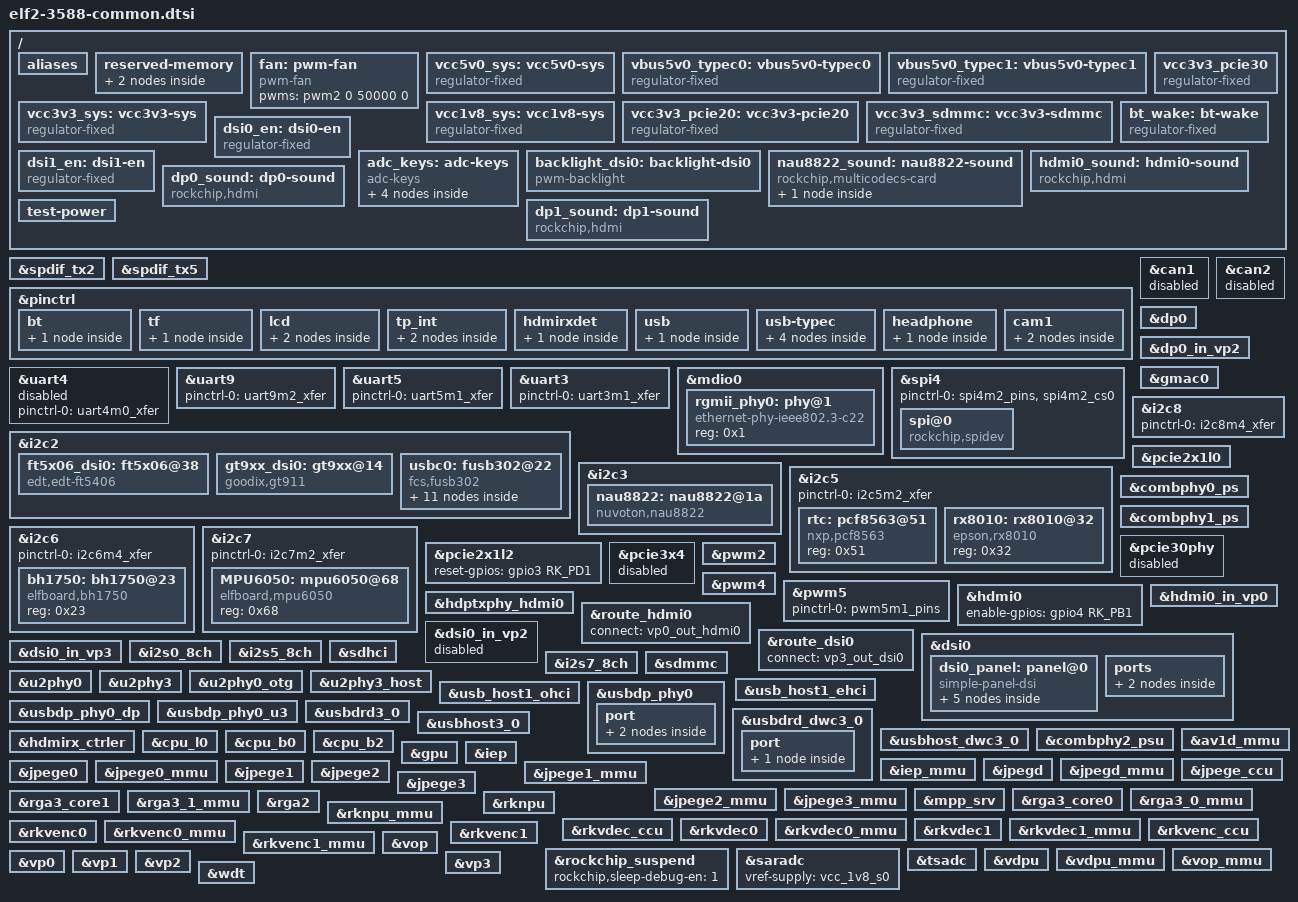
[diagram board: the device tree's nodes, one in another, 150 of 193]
//Readme
//本dtsi由ELF2的ubuntu系统全编译后导出
//修改点：IIC6、IIC7、IIC8、UART3、UART5引脚复用
//Readme

#include "dt-bindings/usb/pd.h"
#include <dt-bindings/gpio/gpio.h>
#include <dt-bindings/pwm/pwm.h>
#include <dt-bindings/pinctrl/rockchip.h>
#include <dt-bindings/input/rk-input.h>
#include <dt-bindings/display/drm_mipi_dsi.h>
#include <dt-bindings/display/rockchip_vop.h>
#include <dt-bindings/sensor-dev.h>

#include "rk3588.dtsi"
#include "elf2-3588.dtsi"
#include "rk3588-rk806-single.dtsi"
#include "elf2-3588-Camera.dtsi"

/ {
	aliases {
	        mmc0 = &sdhci;
	        mmc1 = &sdmmc;
	};

	reserved-memory {
		#address-cells = <2>;
		#size-cells = <2>;
		ranges;
		dma_trans: dma-trans@3c000000 {
			reg = <0x0 0x3c000000 0x0 0x04000000>;
		};

		/* Reserve 256MB memory for hdmirx-controller@fdee0000 */
		cma {
			compatible = "shared-dma-pool";
			reusable;
			reg = <0x0 (256 * 0x100000) 0x0 (256 * 0x100000)>;
			linux,cma-default;
		};
	};

	fan: pwm-fan {
		compatible = "pwm-fan";
		#cooling-cells = <2>;
		pwms = <&pwm2 0 50000 0>;
	};

	vcc5v0_sys: vcc5v0-sys {
		compatible = "regulator-fixed";
		regulator-name = "vcc5v0_sys";
		regulator-always-on;
		regulator-boot-on;
		regulator-min-microvolt = <5000000>;
		regulator-max-microvolt = <5000000>;
		vin-supply = <&vcc12v_dcin>;
	};

    vbus5v0_typec0: vbus5v0-typec0 {
        compatible = "regulator-fixed";
        regulator-name = "vbus5v0_typec0";
        regulator-min-microvolt = <5000000>;
        regulator-max-microvolt = <5000000>;
        enable-active-high;
        gpio = <&gpio0 RK_PD0 GPIO_ACTIVE_HIGH>;
        vin-supply = <&vcc5v0_sys>;
        pinctrl-names = "default";
        pinctrl-0 = <&typec5v_pwren0>;
    };

    vbus5v0_typec1: vbus5v0-typec1 {
        compatible = "regulator-fixed";
        regulator-name = "vbus5v0_typec1";
        regulator-min-microvolt = <5000000>;
        regulator-max-microvolt = <5000000>;
        enable-active-high;
        gpio = <&gpio0 RK_PD3 GPIO_ACTIVE_HIGH>;
        vin-supply = <&vcc5v0_sys>;
        pinctrl-names = "default";
        pinctrl-0 = <&typec5v_pwren1>;
    };

	vcc3v3_sys: vcc3v3-sys {
		compatible = "regulator-fixed";
		regulator-name = "vcc3v3_sys";
		regulator-always-on;
		regulator-boot-on;
		regulator-min-microvolt = <3300000>;
		regulator-max-microvolt = <3300000>;
		vin-supply = <&vcc5v0_sys>;
	};

	vcc1v8_sys: vcc1v8-sys {
		compatible = "regulator-fixed";
		regulator-name = "vcc1v8_sys";
		regulator-always-on;
		regulator-boot-on;
		regulator-min-microvolt = <1800000>;
		regulator-max-microvolt = <1800000>;
		vin-supply = <&vcc3v3_sys>;
	};

	vcc3v3_pcie30: vcc3v3_pcie30 {
		compatible = "regulator-fixed";
		regulator-name = "vcc3v3_pcie30";
		regulator-boot-on;
		regulator-always-on;
		regulator-min-microvolt = <3300000>;
		regulator-max-microvolt = <3300000>;
		vin-supply = <&vcc5v0_sys>;
	};

	vcc3v3_pcie20: vcc3v3-pcie20 {
		compatible = "regulator-fixed";
		regulator-name = "vcc3v3-pcie20";
		regulator-boot-on;
		regulator-always-on;
		regulator-min-microvolt = <3300000>;
		regulator-max-microvolt = <3300000>;
		vin-supply = <&vcc5v0_sys>;
	};

	vcc3v3_sdmmc: vcc3v3-sdmmc {
		compatible = "regulator-fixed";
		regulator-name = "vcc3v3_sdmmc";
		regulator-min-microvolt = <3300000>;
		regulator-max-microvolt = <3300000>;
		enable-active-high;
		regulator-boot-on;
		regulator-always-on;
		gpios = <&gpio2 RK_PC4 GPIO_ACTIVE_HIGH>;
		startup-delay-us = <5000>;
		vin-supply = <&vcc5v0_sys>;
	};

	bt_wake: bt-wake {
		compatible = "regulator-fixed";
		regulator-name = "bt_wake";
		regulator-min-microvolt = <1800000>;
		regulator-max-microvolt = <1800000>;
		enable-active-high;
		regulator-boot-on;
		regulator-always-on;
		gpios = <&gpio1 RK_PA6 GPIO_ACTIVE_HIGH>;
		vin-supply = <&vcc5v0_sys>;
	};

	dsi0_en: dsi0-en {
		compatible = "regulator-fixed";
		pinctrl-names = "default";
		pinctrl-0 = <&mipi0_enable_gpio>;
		regulator-name = "dsi0_en";
		regulator-min-microvolt = <1800000>;
		regulator-max-microvolt = <1800000>;
		enable-active-high;
		regulator-boot-on;
		regulator-always-on;
		gpios = <&gpio3 RK_PB2 GPIO_ACTIVE_HIGH>;
		vin-supply = <&vcc5v0_sys>;
	};
	dsi1_en: dsi1-en {
		compatible = "regulator-fixed";
		pinctrl-names = "default";
		pinctrl-0 = <&mipi1_enable_gpio>;
		regulator-name = "dsi1_en";
		regulator-min-microvolt = <1800000>;
		regulator-max-microvolt = <1800000>;
		enable-active-high;
		regulator-boot-on;
		regulator-always-on;
		gpios = <&gpio3 RK_PC6 GPIO_ACTIVE_HIGH>;
		vin-supply = <&vcc5v0_sys>;
	};

	adc_keys: adc-keys {
		compatible = "adc-keys";
		io-channels = <&saradc 1>;
		io-channel-names = "buttons";
		keyup-threshold-microvolt = <1800000>;
		poll-interval = <100>;

		vol-up-key {
			label = "volume up";
			linux,code = <KEY_VOLUMEUP>;
			press-threshold-microvolt = <17000>;
		};

		vol-down-key {
			label = "volume down";
			linux,code = <KEY_VOLUMEDOWN>;
			press-threshold-microvolt = <417000>;
		};

		menu-key {
			label = "menu";
			linux,code = <KEY_MENU>;
			press-threshold-microvolt = <890000>;
		};

		back-key {
			label = "back";
			linux,code = <KEY_BACK>;
			press-threshold-microvolt = <1235000>;
		};
	};

	backlight_dsi0: backlight-dsi0 {
		compatible = "pwm-backlight";
		pwms = <&pwm5 0 25000 0>;
		status = "okay";
		brightness-levels = <
			  0  20  20  21  21  22  22  23
			 23  24  24  25  25  26  26  27
			 27  28  28  29  29  30  30  31
			 31  32  32  33  33  34  34  35
			 35  36  36  37  37  38  38  39
			 40  41  42  43  44  45  46  47
			 48  49  50  51  52  53  54  55
			 56  57  58  59  60  61  62  63
			 64  65  66  67  68  69  70  71
			 72  73  74  75  76  77  78  79
			 80  81  82  83  84  85  86  87
			 88  89  90  91  92  93  94  95
			 96  97  98  99 100 101 102 103
			104 105 106 107 108 109 110 111
			112 113 114 115 116 117 118 119
			120 121 122 123 124 125 126 127
			128 129 130 131 132 133 134 135
			136 137 138 139 140 141 142 143
			144 145 146 147 148 149 150 151
			152 153 154 155 156 157 158 159
			160 161 162 163 164 165 166 167
			168 169 170 171 172 173 174 175
			176 177 178 179 180 181 182 183
			184 185 186 187 188 189 190 191
			192 193 194 195 196 197 198 199
			200 201 202 203 204 205 206 207
			208 209 210 211 212 213 214 215
			216 217 218 219 220 221 222 223
			224 225 226 227 228 229 230 231
			232 233 234 235 236 237 238 239
			240 241 242 243 244 245 246 247
			248 249 250 251 252 253 254 255
		>;
		default-brightness-level = <200>;
		is-elfboard;
	};

	nau8822_sound: nau8822-sound {
		status = "okay";
		compatible = "rockchip,multicodecs-card";
		rockchip,card-name = "rockchip-nau8822";
		hp-det-gpio = <&gpio1 RK_PB2 GPIO_ACTIVE_HIGH>;
		io-channels = <&saradc 3>;
		io-channel-names = "adc-detect";
		keyup-threshold-microvolt = <1800000>;
		poll-interval = <100>;
//		spk-con-gpio = <&gpio1 RK_PD3 GPIO_ACTIVE_HIGH>;
//		hp-con-gpio = <&gpio1 RK_PD2 GPIO_ACTIVE_HIGH>;
		rockchip,format = "i2s";
		rockchip,mclk-fs = <256>;
		rockchip,cpu = <&i2s0_8ch>;
		rockchip,codec = <&nau8822>;
		rockchip,audio-routing =
			"Headphone", "RHP",
			"Headphone", "LHP",
			"Speaker", "LSPK",
			"Speaker", "RSPK",
			"RMICP", "Main Mic",
			"RMICN", "Main Mic",
			"RMICP", "Headset Mic",
			"RMICN", "Headset Mic",
			"LMICP", "Main Mic",
			"LMICN", "Main Mic",
			"LMICP", "Headset Mic",
			"LMICN", "Headset Mic";
		pinctrl-names = "default";
		pinctrl-0 = <&hp_det>;
		play-pause-key {
			label = "playpause";
			linux,code = <KEY_PLAYPAUSE>;
			press-threshold-microvolt = <2000>;
			poll-interval = <1000>;
		};
	};

	hdmi0_sound: hdmi0-sound {
		status = "okay";
		compatible = "rockchip,hdmi";
		rockchip,mclk-fs = <128>;
		rockchip,card-name = "rockchip-hdmi0";
		rockchip,cpu = <&i2s5_8ch>;
		rockchip,codec = <&hdmi0>;
		rockchip,jack-det;
	};

	dp0_sound: dp0-sound {
		status = "okay";
		compatible = "rockchip,hdmi";
		rockchip,card-name= "rockchip,dp0";
		rockchip,mclk-fs = <512>;
		rockchip,cpu = <&spdif_tx2>;
		rockchip,codec = <&dp0 1>;
		rockchip,jack-det;
	};

	dp1_sound: dp1-sound {
		status = "okay";
		compatible = "rockchip,hdmi";
		rockchip,card-name= "rockchip,dp1";
		rockchip,mclk-fs = <512>;
		rockchip,cpu = <&spdif_tx5>;
		rockchip,codec = <&dp1 1>;
		rockchip,jack-det;
	};

	test-power {
		status = "okay";
	};

};

&spdif_tx2 {
	status = "okay";
};

&spdif_tx5 {
	status = "okay";
};

&pinctrl {

	bt {
		bluetooth_wake_pin: bluetooth-wake-pin {
			rockchip,pins = <1 RK_PA4 RK_FUNC_GPIO &pcfg_pull_none>;
		};
	};
	tf {
		sdmmc_pwren_gpio: sdmmc-pwren-gpio {
			rockchip,pins = <2 RK_PC4 RK_FUNC_GPIO &pcfg_pull_none>;
		};
	};

	lcd {
		mipi0_enable_gpio: mipi0-enable-gpio {
			rockchip,pins = <3 RK_PB2 RK_FUNC_GPIO &pcfg_pull_none>;
		};
		mipi1_enable_gpio: mipi1-enable-gpio {
			rockchip,pins = <3 RK_PC6 RK_FUNC_GPIO &pcfg_pull_none>;
		};
	};

	tp_int {
		ft5x06_dsi1_gpio:  ft5x06-dsi1-gpio {
			rockchip,pins = <3 RK_PC0 RK_FUNC_GPIO &pcfg_pull_none>;
		};

		gt911_dsi1_gpio:gt911-dsi0-gpio {
			rockchip,pins = <3 RK_PB7 RK_FUNC_GPIO &pcfg_pull_none>,
							<3 RK_PC0 RK_FUNC_GPIO &pcfg_pull_none>;
		};

	};

	hdmirxdet {
		hdmirx_det_gpio: hdmirx-det-gpio {
			rockchip,pins = <1 RK_PD5 RK_FUNC_GPIO &pcfg_pull_up>;
		};
	};


	usb {
		vcc5v0_host_en: vcc5v0-host-en {
			rockchip,pins = <4 RK_PB0 RK_FUNC_GPIO &pcfg_pull_none>;
		};
	};

	usb-typec {
		usbc0_int: usbc0-int {
			rockchip,pins = <1 RK_PB0 RK_FUNC_GPIO &pcfg_pull_up>;
		};

		typec5v_pwren0: typec5v-pwren0 {
			rockchip,pins = <0 RK_PD0 RK_FUNC_GPIO &pcfg_pull_none>;
		};

		usbc1_int: usbc1-int {
			rockchip,pins = <1 RK_PB3 RK_FUNC_GPIO &pcfg_pull_up>;
		};

		typec5v_pwren1: typec5v-pwren1 {
			rockchip,pins = <0 RK_PD3 RK_FUNC_GPIO &pcfg_pull_none>;
		};
	};

	headphone {
		hp_det: hp-det {
			rockchip,pins = <1 RK_PB2 RK_FUNC_GPIO &pcfg_pull_none>;
		};
	};

	cam1 {
                cam1_reset_gpio: cam1-reset-gpio {
                        rockchip,pins = <1 RK_PC6 RK_FUNC_GPIO &pcfg_pull_none>;
                };

                cam1_pwren_gpio: cam1-pwren-gpio {
                        rockchip,pins = <1 RK_PD3 RK_FUNC_GPIO &pcfg_pull_none>;
                };
        };
};

&uart4 {
	pinctrl-names = "default";
	pinctrl-0 = <&uart4m0_xfer>;
	status = "disabled";
};


&uart9 {
	pinctrl-names = "default";
	pinctrl-0 = <&uart9m2_xfer>;
	status = "okay";
};

&uart5 {
	pinctrl-names = "default";
	pinctrl-0 = <&uart5m1_xfer>;
	status = "okay";
};

&uart3 {
	pinctrl-names = "default";
	pinctrl-0 = <&uart3m1_xfer>;
	status = "okay";
};

&can1 {
	pinctrl-0 = <&can1m1_pins>;
	status = "disabled";
	assigned-clocks = <&cru CLK_CAN1>;
	assigned-clock-rates = <200000000>;
};

&can2 {
	status = "disabled";
	assigned-clocks = <&cru CLK_CAN2>;
	assigned-clock-rates = <200000000>;
};

&dp0 {
	status = "okay";
};

&dp0_in_vp2 {
	status = "okay";
};

&mdio0 {
	rgmii_phy0: phy@1 {
		compatible = "ethernet-phy-ieee802.3-c22";
		reg = <0x1>;
	};
};


&gmac0 {
	/* Use rgmii-rxid mode to disable rx delay inside Soc */
	phy-mode = "rgmii-rxid";
	clock_in_out = "output";

	snps,reset-gpio = <&gpio0 RK_PB0 GPIO_ACTIVE_LOW>;
	snps,reset-active-low;
	/* Reset time is 20ms, 100ms for rtl8211f */
	snps,reset-delays-us = <0 20000 100000>;

	pinctrl-names = "default";
	pinctrl-0 = <&gmac0_miim
		     &gmac0_tx_bus2
		     &gmac0_rx_bus2
		     &gmac0_rgmii_clk
		     &gmac0_rgmii_bus>;

	tx_delay = <0x44>;
	/* rx_delay = <0x4f>; */

	phy-handle = <&rgmii_phy0>;
	status = "okay";
};


&i2c2 {
	status = "okay";

	ft5x06_dsi0: ft5x06@38 { //dsi0 tp
		compatible = "edt,edt-ft5406", "edt,edt-ft5x06";
		reg = <0x38>;
		pinctrl-names = "ft5x06_defaults";
		pinctrl-0 = <&ft5x06_dsi1_gpio>;
//		interrupt-parent = <&gpio3>;
//		interrupts = <RK_PC0 IRQ_TYPE_EDGE_FALLING>;
        irq-gpio = <&gpio3 RK_PC0 GPIO_ACTIVE_HIGH>;
		touchscreen-size-x = <1024>;
		touchscreen-size-y = <600>;
		status = "okay";
	};

	gt9xx_dsi0: gt9xx@14 {
        compatible = "goodix,gt911";
        reg = <0x14>;
        pinctrl-names = "gt9xx_default";
        pinctrl-0 = <&gt911_dsi1_gpio>;
        //interrupt-parent = <&gpio3>;
        //interrupts = <RK_PC0 IRQ_TYPE_EDGE_FALLING>;
        irq-gpio = <&gpio3 RK_PC0 GPIO_ACTIVE_HIGH>;
        reset-gpio = <&gpio3 RK_PB7 GPIO_ACTIVE_HIGH>;
        touchscreen-size-x = <1024>;
        touchscreen-size-y = <600>;
		is-mutex;
		filter-reg = <0x38>;
		bus-reg = <0x02>;
        status = "okay";
    };

	usbc0: fusb302@22 {
		compatible = "fcs,fusb302";
		reg = <0x22>;
		interrupt-parent = <&gpio1>;
		interrupts = <RK_PB0 IRQ_TYPE_LEVEL_LOW>;
		pinctrl-names = "default";
		pinctrl-0 = <&usbc0_int>;
		vbus-supply = <&vbus5v0_typec0>;
		status = "okay";

		ports {
			#address-cells = <1>;
			#size-cells = <0>;

			port@0 {
				reg = <0>;
				usbc0_role_sw: endpoint@0 {
					remote-endpoint = <&dwc3_0_role_switch>;
				};
			};
		};

		usb_con0: connector {
			compatible = "usb-c-connector";
			label = "USB-C";
			data-role = "dual";
			power-role = "dual";
			try-power-role = "sink";
			op-sink-microwatt = <1000000>;
			sink-pdos =
				<PDO_FIXED(5000, 1000, PDO_FIXED_USB_COMM)>;
			source-pdos =
				<PDO_FIXED(5000, 3000, PDO_FIXED_USB_COMM)>;

			altmodes {
				#address-cells = <1>;
				#size-cells = <0>;

				altmode@0 {
					reg = <0>;
					svid = <0xff01>;
					vdo = <0xffffffff>;
				};
			};

			ports {
				#address-cells = <1>;
				#size-cells = <0>;

				port@0 {
					reg = <0>;
					usbc0_orien_sw: endpoint {
						remote-endpoint = <&usbdp_phy0_orientation_switch>;
					};
				};

				port@1 {
					reg = <1>;
					dp0_altmode_mux: endpoint {
						remote-endpoint = <&usbdp_phy0_dp_altmode_mux>;
					};
				};
			};
		};
	};

};


&spi4 {
       status = "okay";
        pinctrl-names = "default";
        pinctrl-0 = <&spi4m2_pins
                    &spi4m2_cs0>;
	spi@0 {
		compatible = "rockchip,spidev";
		reg = <0>;
		spi-max-frequency = <50000000>;
	};
};

&i2c3 {
	status = "okay";
        nau8822: nau8822@1a {
                status = "okay";
                #sound-dai-cells = <0>;
                compatible = "nuvoton,nau8822";
                reg = <0x1a>;
                clocks = <&mclkout_i2s0>;
                clock-names = "mclk";
                assigned-clocks = <&mclkout_i2s0>;
                assigned-clock-rates = <12288000>;
                pinctrl-names = "default";
                pinctrl-0 = <&i2s0_mclk>;
        };
};

&i2c5 {
	status = "okay";
	pinctrl-names = "default";
	pinctrl-0 = <&i2c5m2_xfer>;

	rtc: pcf8563@51 {
		compatible = "nxp,pcf8563";
		reg = <0x51>;
		status = "okay";
	};

	rx8010:rx8010@32 {
		compatible = "epson,rx8010";
		reg = <0x32>;
		status = "okay";
	};

};

&i2c6 {
	status = "okay";
	pinctrl-names = "default";
	pinctrl-0 = <&i2c6m4_xfer>;
	bh1750:bh1750@23 {
	compatible = "elfboard,bh1750";
	reg = <0x23>;
	status ="okay";
	
	};	
};

&i2c7 {
	status = "okay";
	pinctrl-names = "default";
	pinctrl-0 = <&i2c7m2_xfer>;
	MPU6050:mpu6050@68 {
	compatible = "elfboard,mpu6050";
	reg = <0x68>;
	status ="okay";	
	};
};


&i2c8 {
	status = "okay";
	pinctrl-names = "default";
	pinctrl-0 = <&i2c8m4_xfer>;	
};

&pcie2x1l0 {
	reset-gpios = <&gpio4 RK_PA5 GPIO_ACTIVE_HIGH>;
	vpcie3v3-supply = <&vcc3v3_pcie20>;
	status = "okay";
};

&combphy0_ps {
	status = "okay";
};

&pcie2x1l2 {
	reset-gpios = <&gpio3 RK_PD1 GPIO_ACTIVE_HIGH>;
	status = "okay";
};

&combphy1_ps {
	status = "okay";
};

&pcie30phy {
	rockchip,pcie30-phymode = <PHY_MODE_PCIE_AGGREGATION>;
	status = "disabled";
};

&pcie3x4 {
	reset-gpios = <&gpio4 RK_PB6 GPIO_ACTIVE_HIGH>;
	memory-region = <&dma_trans>;
	vpcie3v3-supply = <&vcc3v3_pcie30>;
	status = "disabled";
};


&pwm2 { 
	status = "okay";
};

&pwm4 { 
	status = "okay";
};

&pwm5 {//dsi0
	pinctrl-0 = <&pwm5m1_pins>;
	status = "okay";
};


&hdmi0 {
	enable-gpios = <&gpio4 RK_PB1 GPIO_ACTIVE_HIGH>;
	status = "okay";
};

&hdmi0_in_vp0 {
	status = "okay";
};

&hdptxphy_hdmi0 {
	status = "okay";
};

&route_hdmi0 {
	status = "okay";
	connect = <&vp0_out_hdmi0>;
//	force-output;

//	force_timing {
//		clock-frequency = <65000000>;
//		hactive = <1024>;
//		vactive = <768>;
//		hfront-porch = <24>;
//		hsync-len = <136>;
//		hback-porch = <160>;
//		vfront-porch = <3>;
//		vsync-len = <6>;
//		vback-porch = <29>;
//		hsync-active = <0>;
//		vsync-active = <0>;
//		de-active = <0>;
//		pixelclk-active = <0>;
//	};

};


&route_dsi0 {
	status = "okay";
	connect = <&vp3_out_dsi0>;
};

&dsi0 {
	status = "okay";
	//rockchip,lane-rate = <1000>;
	dsi0_panel: panel@0 {
		status = "okay";
//		pinctrl-names = "default";
//		pinctrl-0 = <&mipi0_enable_gpio>;
		compatible = "simple-panel-dsi";
		reg = <0>;
		backlight = <&backlight_dsi0>;
		reset-delay-ms = <10>;
		enable-delay-ms = <10>;
		prepare-delay-ms = <10>;
		unprepare-delay-ms = <10>;
		disable-delay-ms = <60>;
		dsi,flags = <(MIPI_DSI_MODE_VIDEO | MIPI_DSI_MODE_VIDEO_BURST |
			MIPI_DSI_MODE_LPM | MIPI_DSI_MODE_EOT_PACKET)>;
		dsi,format = <MIPI_DSI_FMT_RGB888>;
		dsi,lanes  = <4>;
//		enable-gpios = <&gpio3 RK_PB2 GPIO_ACTIVE_HIGH>;

//		panel-init-sequence = [
//		];

//		panel-exit-sequence = [
//		];

		panel0_disp_timings0: display-timings {
			native-mode = <&panel0_7_1024x600>;
            panel0_7_1024x600: timings {
                hback-porch     = <48>;
                hfront-porch    = <40>;
                hactive                 = <1024>;
                hsync-len               = <48>;
                vback-porch     = <48>;
                vfront-porch    = <40>;
                vactive         = <600>;
                vsync-len       = <4>;
                clock-frequency = <45000000>;
                vsync-active    = <0>;
                hsync-active    = <0>;
                de-active       = <0>;
                pixelclk-active = <0>;
            };
		};

		ports {
			#address-cells = <1>;
			#size-cells = <0>;

			port@0 {
				reg = <0>;
				panel_in_dsi0: endpoint {
					remote-endpoint = <&dsi0_out_panel>;
				};
			};
		};
	};

	ports {
		#address-cells = <1>;
		#size-cells = <0>;

		port@1 {
			reg = <1>;
			dsi0_out_panel: endpoint {
				remote-endpoint = <&panel_in_dsi0>;
			};
		};
	};

};

/*
 * mipi_dcphy0 needs to be enabled
 * when dsi0 is enabled
 */
&dsi0 {
	status = "okay";
};

&dsi0_in_vp2 {
	status = "disabled";
};

&dsi0_in_vp3 {
	status = "okay";
};


&i2s0_8ch {
	status = "okay";
	pinctrl-0 = <&i2s0_lrck
		     &i2s0_sclk
		     &i2s0_sdi0
		     &i2s0_sdo0>;
};

&i2s5_8ch {
	status = "okay";
};


&i2s7_8ch {
    status = "okay";
};

&sdhci {
	bus-width = <8>;
	no-sdio;
	no-sd;
	non-removable;
	max-frequency = <200000000>;
	mmc-hs400-1_8v;
	mmc-hs400-enhanced-strobe;
	status = "okay";
};

&sdmmc {
	max-frequency = <150000000>;
	no-sdio;
	no-mmc;
	bus-width = <4>;
	cap-mmc-highspeed;
	cap-sd-highspeed;
	disable-wp;
	sd-uhs-sdr104;
	vqmmc-supply = <&vccio_sd_s0>;
	cd-gpios = <&gpio0 RK_PA4 GPIO_ACTIVE_LOW>;
	status = "okay";
};

&u2phy0 {
	status = "okay";
};

&u2phy3 {
	status = "okay";
};

&u2phy0_otg {
	status = "okay";
};

&u2phy3_host {
	status = "okay";
};

&usb_host1_ehci {
	status = "okay";
};

&usb_host1_ohci {
	status = "okay";
};

&usbdp_phy0 {
	status = "okay";
	orientation-switch;
	rockchip,dp-lane-mux = <2 3>;
	svid = <0xff01>;
	sbu1-dc-gpios = <&gpio4 RK_PA0 GPIO_ACTIVE_HIGH>;
	sbu2-dc-gpios = <&gpio4 RK_PB0 GPIO_ACTIVE_HIGH>;

	port {
		#address-cells = <1>;
		#size-cells = <0>;
		usbdp_phy0_orientation_switch: endpoint@0 {
			reg = <0>;
			remote-endpoint = <&usbc0_orien_sw>;
		};

		usbdp_phy0_dp_altmode_mux: endpoint@1 {
			reg = <1>;
			remote-endpoint = <&dp0_altmode_mux>;
		};
	};
};

&usbdp_phy0_dp {
	status = "okay";
};

&usbdp_phy0_u3 {
	status = "okay";
};

&usbdrd3_0 {
	status = "okay";
};

&usbdrd_dwc3_0 {
	dr_mode = "otg";
	usb-role-switch;
	status = "okay";
	port {
		#address-cells = <1>;
		#size-cells = <0>;
		dwc3_0_role_switch: endpoint@0 {
			reg = <0>;
			remote-endpoint = <&usbc0_role_sw>;
		};
	};
};

&usbhost3_0 {
	status = "okay";
};

&usbhost_dwc3_0 {
	status = "okay";
};

&combphy2_psu {
	status = "okay";
};

/* Should work with at least 128MB cma reserved above. */
&hdmirx_ctrler {
	status = "okay";
	pinctrl-names = "default";
	pinctrl-0 = <&hdmim2_rx_cec &hdmim2_rx_hpdin &hdmim2_rx_scl &hdmim2_rx_sda &hdmirx_det_gpio>;

	/* Effective level used to trigger HPD: 0-low, 1-high */
	hpd-trigger-level = <1>;
	hdmirx-det-gpios = <&gpio1 RK_PD5 GPIO_ACTIVE_LOW>;
};

&av1d_mmu {
	status = "okay";
};

&cpu_l0 {
	cpu-supply = <&vdd_cpu_lit_s0>;
	mem-supply = <&vdd_cpu_lit_mem_s0>;
};

&cpu_b0 {
	cpu-supply = <&vdd_cpu_big0_s0>;
	mem-supply = <&vdd_cpu_big0_mem_s0>;
};

&cpu_b2 {
	cpu-supply = <&vdd_cpu_big1_s0>;
	mem-supply = <&vdd_cpu_big1_mem_s0>;
};

&gpu {
	mali-supply = <&vdd_gpu_s0>;
	mem-supply = <&vdd_gpu_mem_s0>;
	status = "okay";
};

&iep {
	status = "okay";
};

&iep_mmu {
	status = "okay";
};

&jpegd {
	status = "okay";
};

&jpegd_mmu {
	status = "okay";
};

&jpege_ccu {
	status = "okay";
};

&jpege0 {
	status = "okay";
};

&jpege0_mmu {
	status = "okay";
};

&jpege1 {
	status = "okay";
};

&jpege1_mmu {
	status = "okay";
};

&jpege2 {
	status = "okay";
};

&jpege2_mmu {
	status = "okay";
};

&jpege3 {
	status = "okay";
};

&jpege3_mmu {
	status = "okay";
};

&mpp_srv {
	status = "okay";
};

&rga3_core0 {
	status = "okay";
};

&rga3_0_mmu {
	status = "okay";
};

&rga3_core1 {
	status = "okay";
};

&rga3_1_mmu {
	status = "okay";
};

&rga2 {
	status = "okay";
};

&rknpu {
	rknpu-supply = <&vdd_npu_s0>;
	mem-supply = <&vdd_npu_mem_s0>;
	status = "okay";
};

&rknpu_mmu {
	status = "okay";
};

&rkvdec_ccu {
	status = "okay";
};

&rkvdec0 {
	status = "okay";
};

&rkvdec0_mmu {
	status = "okay";
};

&rkvdec1 {
	status = "okay";
};

&rkvdec1_mmu {
	status = "okay";
};

&rkvenc_ccu {
	status = "okay";
};

&rkvenc0 {
	status = "okay";
};

&rkvenc0_mmu {
	status = "okay";
};

&rkvenc1 {
	status = "okay";
};

&rkvenc1_mmu {
	status = "okay";
};

&rockchip_suspend {
	status = "okay";
	rockchip,sleep-debug-en = <1>;
};

&saradc {
	status = "okay";
	vref-supply = <&vcc_1v8_s0>;
};

&tsadc {
	status = "okay";
};

&vdpu {
	status = "okay";
};

&vdpu_mmu {
	status = "okay";
};

&vop {
	status = "okay";
};

&vop_mmu {
	status = "okay";
};

/* vp0 & vp1 splice for 8K output */
&vp0 {
	rockchip,plane-mask = <(1 << ROCKCHIP_VOP2_CLUSTER0 | 1 << ROCKCHIP_VOP2_ESMART0)>;
	rockchip,primary-plane = <ROCKCHIP_VOP2_ESMART0>;
};

&vp1 {
	rockchip,plane-mask = <(1 << ROCKCHIP_VOP2_CLUSTER1 | 1 << ROCKCHIP_VOP2_ESMART1)>;
	rockchip,primary-plane = <ROCKCHIP_VOP2_ESMART1>;
};

&vp2 {
	rockchip,plane-mask = <(1 << ROCKCHIP_VOP2_CLUSTER2 | 1 << ROCKCHIP_VOP2_ESMART2)>;
	rockchip,primary-plane = <ROCKCHIP_VOP2_ESMART2>;
};

&vp3 {
	rockchip,plane-mask = <(1 << ROCKCHIP_VOP2_CLUSTER3 | 1 << ROCKCHIP_VOP2_ESMART3)>;
	rockchip,primary-plane = <ROCKCHIP_VOP2_ESMART3>;
};

&wdt {
	status = "okay";
};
